# mc200 register map
Registers are 32-bit, access not given, no defined reset value unless marked. A register's access mark holds for its fields unless they carry their own. Addresses are absolute; registers are grouped by the start of their names; [hi:lo] are bit positions; {n}, {i} and the like mark numbered series.

## GPT0
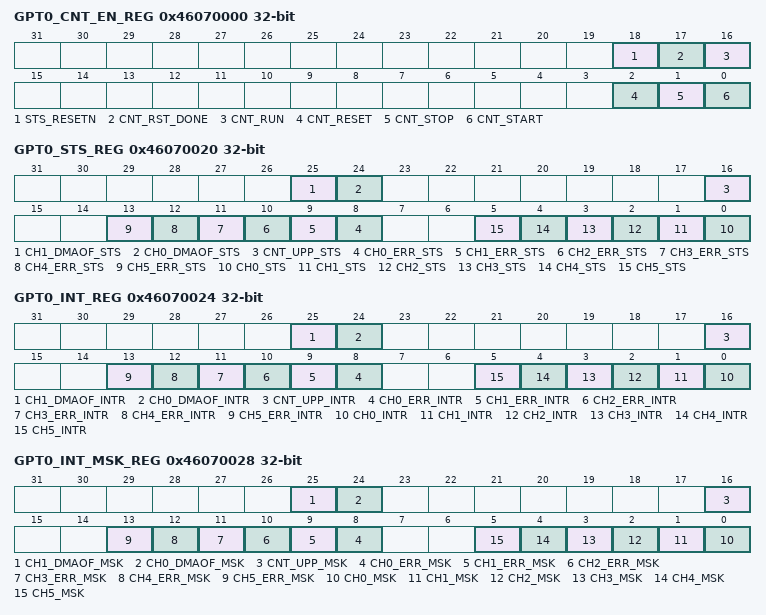
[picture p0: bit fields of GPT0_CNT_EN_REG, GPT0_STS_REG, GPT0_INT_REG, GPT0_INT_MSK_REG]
0x46070000 GPT0_CNT_EN_REG
  [18] STS_RESETN, [17] CNT_RST_DONE, [16] CNT_RUN, [2] CNT_RESET, [1] CNT_STOP, [0] CNT_START
0x46070020 GPT0_STS_REG
  [25] CH1_DMAOF_STS, [24] CH0_DMAOF_STS, [16] CNT_UPP_STS, [n+8] CH{n}_ERR_STS (n=0..5), [n] CH{n}_STS (n=0..5)
0x46070024 GPT0_INT_REG
  [25] CH1_DMAOF_INTR, [24] CH0_DMAOF_INTR, [16] CNT_UPP_INTR, [n+8] CH{n}_ERR_INTR (n=0..5), [n] CH{n}_INTR (n=0..5)
0x46070028 GPT0_INT_MSK_REG
  [25] CH1_DMAOF_MSK, [24] CH0_DMAOF_MSK, [16] CNT_UPP_MSK, [n+8] CH{n}_ERR_MSK (n=0..5), [n] CH{n}_MSK (n=0..5)
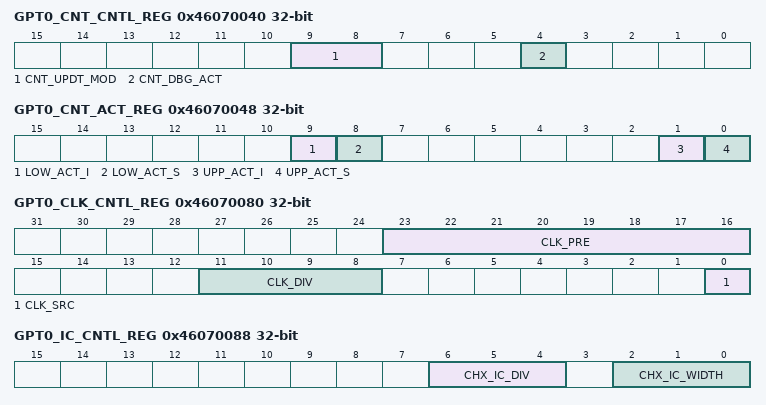
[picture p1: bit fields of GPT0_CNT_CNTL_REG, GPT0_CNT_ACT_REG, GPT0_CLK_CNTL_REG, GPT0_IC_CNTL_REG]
0x46070040 GPT0_CNT_CNTL_REG
  [9:8] CNT_UPDT_MOD, [4] CNT_DBG_ACT
0x46070048 GPT0_CNT_ACT_REG
  [9] LOW_ACT_I, [8] LOW_ACT_S, [1] UPP_ACT_I, [0] UPP_ACT_S
0x46070050 GPT0_CNT_VAL_REG
  [31:0] CNT_VAL
0x46070060 GPT0_CNT_UPP_VAL_REG
  [31:0] UPP_VAL
0x46070080 GPT0_CLK_CNTL_REG
  [23:16] CLK_PRE, [11:8] CLK_DIV, [0] CLK_SRC
0x46070088 GPT0_IC_CNTL_REG
  [6:4] CHX_IC_DIV, [2:0] CHX_IC_WIDTH
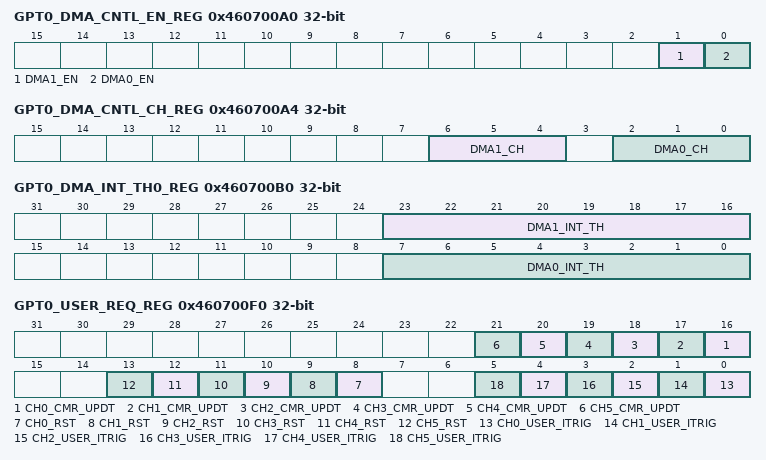
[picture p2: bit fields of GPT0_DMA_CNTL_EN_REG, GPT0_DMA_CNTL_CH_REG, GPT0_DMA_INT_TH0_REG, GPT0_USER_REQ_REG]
0x460700A0 GPT0_DMA_CNTL_EN_REG
  [1] DMA1_EN, [0] DMA0_EN
0x460700A4 GPT0_DMA_CNTL_CH_REG
  [6:4] DMA1_CH, [2:0] DMA0_CH
0x460700B0 GPT0_DMA_INT_TH0_REG
  [23:16] DMA1_INT_TH, [7:0] DMA0_INT_TH
0x460700D0 GPT0_ADCT_REG
  [2:0] ADCT_CHSEL
0x460700D8 GPT0_ADCT_DLY_REG
  [31:0] ADCT_DLY
0x460700F0 GPT0_USER_REQ_REG
  [n+16] CH{n}_CMR_UPDT (n=0..5), [n+8] CH{n}_RST (n=0..5), [n] CH{n}_USER_ITRIG (n=0..5)
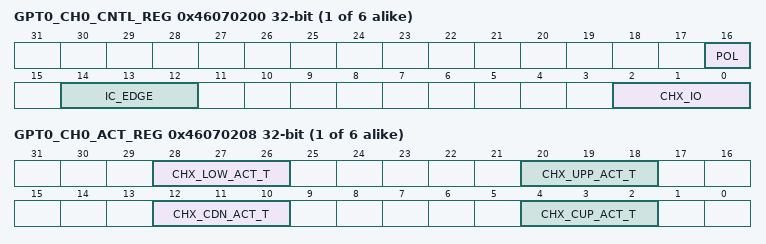
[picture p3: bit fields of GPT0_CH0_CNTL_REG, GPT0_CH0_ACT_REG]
{0x46070200+0x40*i} GPT0_CH{i}_CNTL_REG (i=0..5)
  [16] POL, [14:12] IC_EDGE, [2:0] CHX_IO
{0x46070208+0x40*i} GPT0_CH{i}_ACT_REG (i=0..5)
  [28:26] CHX_LOW_ACT_T, [20:18] CHX_UPP_ACT_T, [12:10] CHX_CDN_ACT_T, [4:2] CHX_CUP_ACT_T
{0x46070210+0x40*i} GPT0_CH{i}_CMR0_REG (i=0..5)
  [29:0] CMR0
{0x46070214+0x40*i} GPT0_CH{i}_STS_REG (i=0..5)
  [0] OUT_ST
{0x46070220+0x40*i} GPT0_CH{i}_CMR1_REG (i=0..5)
  [29:0] CMR1

## GPT1
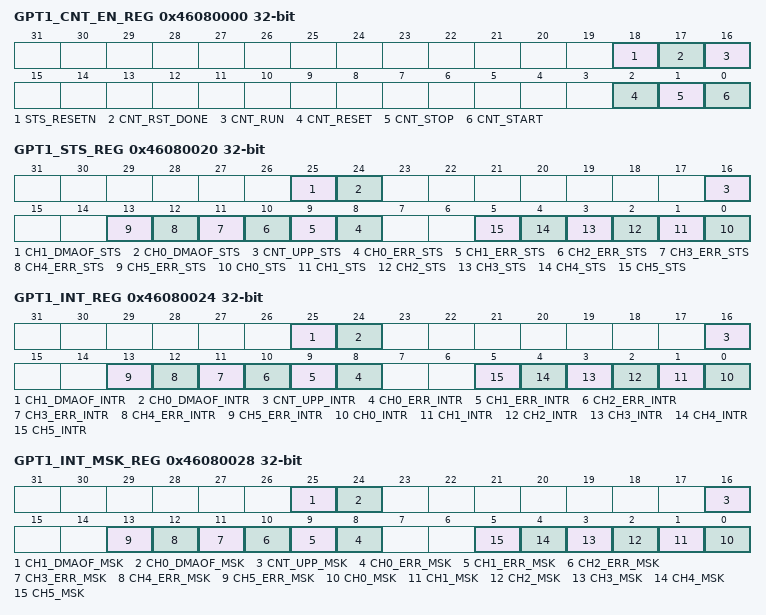
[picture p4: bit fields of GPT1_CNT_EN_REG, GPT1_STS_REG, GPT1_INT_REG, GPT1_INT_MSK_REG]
0x46080000 GPT1_CNT_EN_REG
  [18] STS_RESETN, [17] CNT_RST_DONE, [16] CNT_RUN, [2] CNT_RESET, [1] CNT_STOP, [0] CNT_START
0x46080020 GPT1_STS_REG
  [25] CH1_DMAOF_STS, [24] CH0_DMAOF_STS, [16] CNT_UPP_STS, [n+8] CH{n}_ERR_STS (n=0..5), [n] CH{n}_STS (n=0..5)
0x46080024 GPT1_INT_REG
  [25] CH1_DMAOF_INTR, [24] CH0_DMAOF_INTR, [16] CNT_UPP_INTR, [n+8] CH{n}_ERR_INTR (n=0..5), [n] CH{n}_INTR (n=0..5)
0x46080028 GPT1_INT_MSK_REG
  [25] CH1_DMAOF_MSK, [24] CH0_DMAOF_MSK, [16] CNT_UPP_MSK, [n+8] CH{n}_ERR_MSK (n=0..5), [n] CH{n}_MSK (n=0..5)
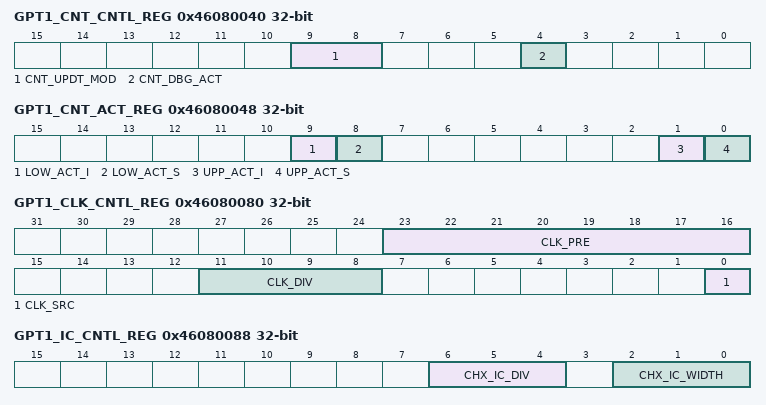
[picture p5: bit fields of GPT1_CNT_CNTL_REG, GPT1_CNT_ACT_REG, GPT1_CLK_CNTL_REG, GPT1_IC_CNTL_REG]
0x46080040 GPT1_CNT_CNTL_REG
  [9:8] CNT_UPDT_MOD, [4] CNT_DBG_ACT
0x46080048 GPT1_CNT_ACT_REG
  [9] LOW_ACT_I, [8] LOW_ACT_S, [1] UPP_ACT_I, [0] UPP_ACT_S
0x46080050 GPT1_CNT_VAL_REG
  [31:0] CNT_VAL
0x46080060 GPT1_CNT_UPP_VAL_REG
  [31:0] UPP_VAL
0x46080080 GPT1_CLK_CNTL_REG
  [23:16] CLK_PRE, [11:8] CLK_DIV, [0] CLK_SRC
0x46080088 GPT1_IC_CNTL_REG
  [6:4] CHX_IC_DIV, [2:0] CHX_IC_WIDTH
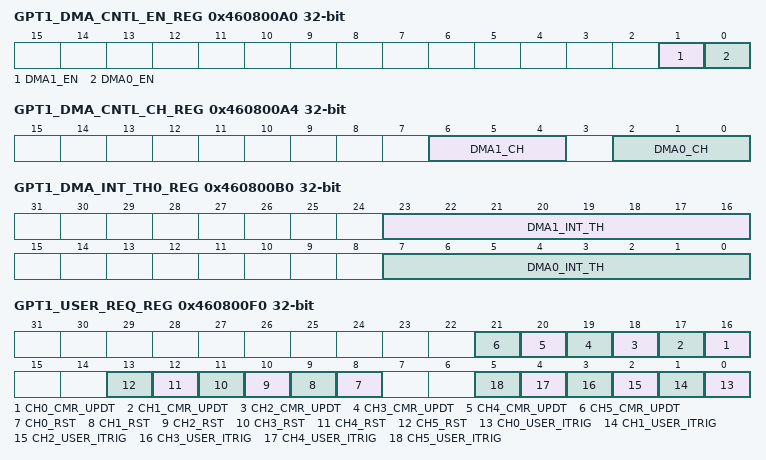
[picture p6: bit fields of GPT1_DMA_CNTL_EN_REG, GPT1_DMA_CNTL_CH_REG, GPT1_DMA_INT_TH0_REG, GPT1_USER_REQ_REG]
0x460800A0 GPT1_DMA_CNTL_EN_REG
  [1] DMA1_EN, [0] DMA0_EN
0x460800A4 GPT1_DMA_CNTL_CH_REG
  [6:4] DMA1_CH, [2:0] DMA0_CH
0x460800B0 GPT1_DMA_INT_TH0_REG
  [23:16] DMA1_INT_TH, [7:0] DMA0_INT_TH
0x460800D0 GPT1_ADCT_REG
  [2:0] ADCT_CHSEL
0x460800D8 GPT1_ADCT_DLY_REG
  [31:0] ADCT_DLY
0x460800F0 GPT1_USER_REQ_REG
  [n+16] CH{n}_CMR_UPDT (n=0..5), [n+8] CH{n}_RST (n=0..5), [n] CH{n}_USER_ITRIG (n=0..5)
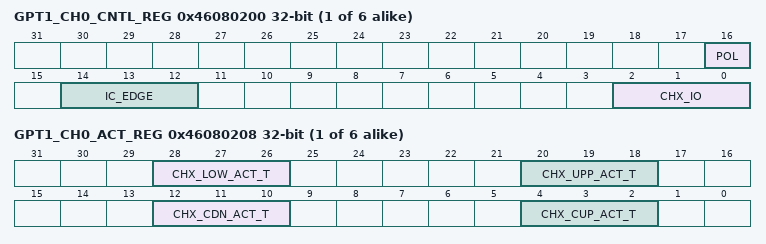
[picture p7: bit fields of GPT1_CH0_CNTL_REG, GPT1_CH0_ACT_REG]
{0x46080200+0x40*i} GPT1_CH{i}_CNTL_REG (i=0..5)
  [16] POL, [14:12] IC_EDGE, [2:0] CHX_IO
{0x46080208+0x40*i} GPT1_CH{i}_ACT_REG (i=0..5)
  [28:26] CHX_LOW_ACT_T, [20:18] CHX_UPP_ACT_T, [12:10] CHX_CDN_ACT_T, [4:2] CHX_CUP_ACT_T
{0x46080210+0x40*i} GPT1_CH{i}_CMR0_REG (i=0..5)
  [29:0] CMR0
{0x46080214+0x40*i} GPT1_CH{i}_STS_REG (i=0..5)
  [0] OUT_ST
{0x46080220+0x40*i} GPT1_CH{i}_CMR1_REG (i=0..5)
  [29:0] CMR1

## QSPI1
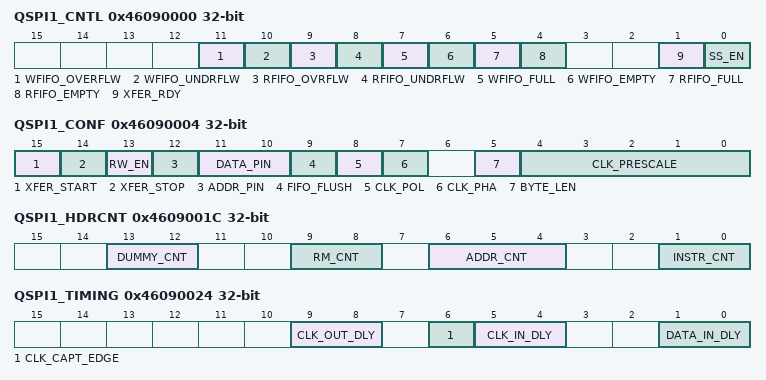
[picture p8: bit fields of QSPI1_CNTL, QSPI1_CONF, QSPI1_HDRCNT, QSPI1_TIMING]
0x46090000 QSPI1_CNTL
  [11] WFIFO_OVERFLW, [10] WFIFO_UNDRFLW, [9] RFIFO_OVRFLW, [8] RFIFO_UNDRFLW, [7] WFIFO_FULL, [6] WFIFO_EMPTY, [5] RFIFO_FULL, [4] RFIFO_EMPTY, [1] XFER_RDY, [0] SS_EN
0x46090004 QSPI1_CONF
  [15] XFER_START, [14] XFER_STOP, [13] RW_EN, [12] ADDR_PIN, [11:10] DATA_PIN, [9] FIFO_FLUSH, [8] CLK_POL, [7] CLK_PHA, [5] BYTE_LEN, [4:0] CLK_PRESCALE
0x46090008 QSPI1_DOUT
  [31:0] DATA_OUT
0x4609000C QSPI1_DIN
  [31:0] DATA_IN
0x46090010 QSPI1_INSTR
  [15:0] INSTR
0x46090014 QSPI1_ADDR
0x46090018 QSPI1_RDMODE
  [15:0] RMODE
0x4609001C QSPI1_HDRCNT
  [13:12] DUMMY_CNT, [9:8] RM_CNT, [6:4] ADDR_CNT, [1:0] INSTR_CNT
0x46090020 QSPI1_DINCNT
  [19:0] DATA_IN_CNT
0x46090024 QSPI1_TIMING
  [9:8] CLK_OUT_DLY, [6] CLK_CAPT_EDGE, [5:4] CLK_IN_DLY, [1:0] DATA_IN_DLY
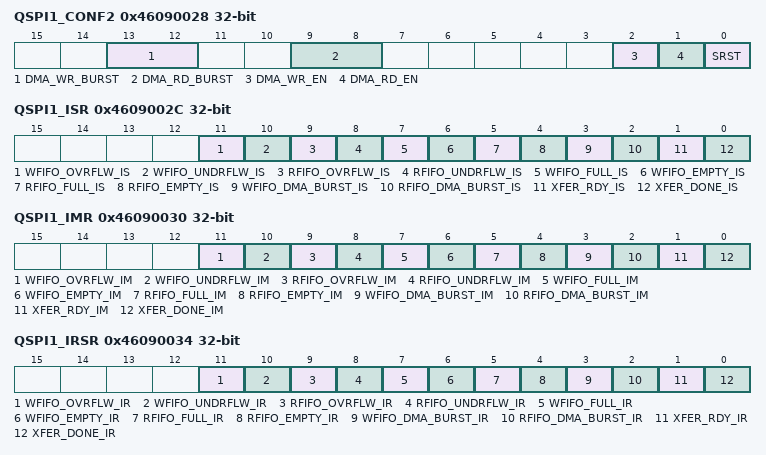
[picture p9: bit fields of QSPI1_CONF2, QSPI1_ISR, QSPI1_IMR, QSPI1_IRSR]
0x46090028 QSPI1_CONF2
  [13:12] DMA_WR_BURST, [9:8] DMA_RD_BURST, [2] DMA_WR_EN, [1] DMA_RD_EN, [0] SRST
0x4609002C QSPI1_ISR
  [11] WFIFO_OVRFLW_IS, [10] WFIFO_UNDRFLW_IS, [9] RFIFO_OVRFLW_IS, [8] RFIFO_UNDRFLW_IS, [7] WFIFO_FULL_IS, [6] WFIFO_EMPTY_IS, [5] RFIFO_FULL_IS, [4] RFIFO_EMPTY_IS, [3] WFIFO_DMA_BURST_IS, [2] RFIFO_DMA_BURST_IS, [1] XFER_RDY_IS, [0] XFER_DONE_IS
0x46090030 QSPI1_IMR
  [11] WFIFO_OVRFLW_IM, [10] WFIFO_UNDRFLW_IM, [9] RFIFO_OVRFLW_IM, [8] RFIFO_UNDRFLW_IM, [7] WFIFO_FULL_IM, [6] WFIFO_EMPTY_IM, [5] RFIFO_FULL_IM, [4] RFIFO_EMPTY_IM, [3] WFIFO_DMA_BURST_IM, [2] RFIFO_DMA_BURST_IM, [1] XFER_RDY_IM, [0] XFER_DONE_IM
0x46090034 QSPI1_IRSR
  [11] WFIFO_OVRFLW_IR, [10] WFIFO_UNDRFLW_IR, [9] RFIFO_OVRFLW_IR, [8] RFIFO_UNDRFLW_IR, [7] WFIFO_FULL_IR, [6] WFIFO_EMPTY_IR, [5] RFIFO_FULL_IR, [4] RFIFO_EMPTY_IR, [3] WFIFO_DMA_BURST_IR, [2] RFIFO_DMA_BURST_IR, [1] XFER_RDY_IR, [0] XFER_DONE_IR
0x46090038 QSPI1_ISC
  [0] XFER_DONE_IC
